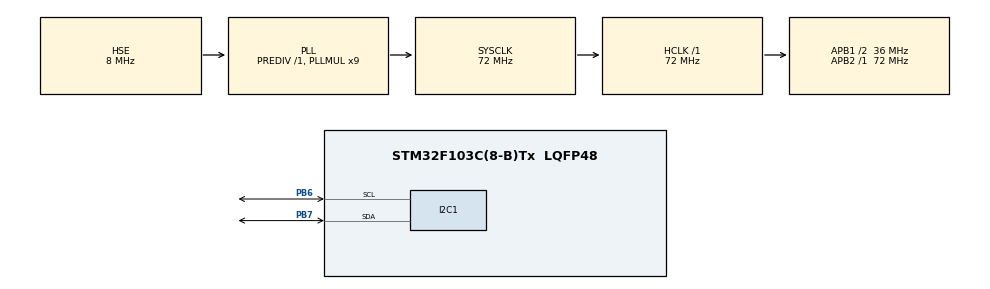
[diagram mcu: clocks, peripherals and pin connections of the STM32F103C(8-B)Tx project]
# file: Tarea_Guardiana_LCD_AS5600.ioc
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Mcu.Family=STM32F1
RCC.PLLSourceVirtual=RCC_PLLSOURCE_HSE
PD1-OSC_OUT.Mode=HSE-External-Oscillator
NVIC.TIM1_UP_IRQn=true\:0\:0\:false\:false\:true\:false\:true
PD0-OSC_IN.Signal=RCC_OSC_IN
RCC.APB1CLKDivider=RCC_HCLK_DIV2
RCC.SYSCLKSource=RCC_SYSCLKSOURCE_PLLCLK
ProjectManager.StackSize=0x400
PD1-OSC_OUT.Signal=RCC_OSC_OUT
PA13.Signal=SYS_JTMS-SWDIO
ProjectManager.TargetToolchain=STM32CubeIDE
RCC.HCLKFreq_Value=72000000
RCC.APB2TimFreq_Value=72000000
PB6.Signal=I2C1_SCL
PB6.Mode=I2C
RCC.USBFreq_Value=72000000
RCC.AHBFreq_Value=72000000
PD0-OSC_IN.Mode=HSE-External-Oscillator
board=custom
RCC.PLLMUL=RCC_PLL_MUL9
RCC.APB2Freq_Value=72000000
PA14.Mode=Serial_Wire
VP_SYS_VS_tim1.Mode=TIM1
PB7.Signal=I2C1_SDA
PA13.Mode=Serial_Wire
Mcu.Name=STM32F103C(8-B)Tx
RCC.SYSCLKFreq_VALUE=72000000
Mcu.Package=LQFP48
NVIC.TimeBase=TIM1_UP_IRQn
PB7.Mode=I2C
NVIC.TimeBaseIP=TIM1
PA14.Signal=SYS_JTCK-SWCLK
ProjectManager.HeapSize=0x200
NVIC.PriorityGroup=NVIC_PRIORITYGROUP_4
RCC.APB1TimFreq_Value=72000000
RCC.APB1Freq_Value=36000000

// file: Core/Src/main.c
/* USER CODE BEGIN Header */
/**
  ******************************************************************************
  * @file           : main.c
  * @brief          : Main program body
  ******************************************************************************
  * @attention
  *
  * <h2><center>&copy; Copyright (c) 2025 STMicroelectronics.
  * All rights reserved.</center></h2>
  *
  * This software component is licensed by ST under BSD 3-Clause license,
  * the "License"; You may not use this file except in compliance with the
  * License. You may obtain a copy of the License at:
  *                        opensource.org/licenses/BSD-3-Clause
  *
  ******************************************************************************
  */
/* USER CODE END Header */
#include "main.h"
#include "FreeRTOS.h"
#include "task.h"
#include "queue.h"
#include "lcd_i2c.h"
#include <stdio.h>
#include "i2c_shared.h"

I2C_HandleTypeDef hi2c1;

/* USER CODE BEGIN PV */

QueueHandle_t I2C_txQueue;
QueueHandle_t I2C_rxQueue;
QueueHandle_t angleQueue;

/* USER CODE END PV */

void SystemClock_Config(void);
static void MX_GPIO_Init(void);
static void MX_I2C1_Init(void);

/* USER CODE BEGIN 0 */

void I2C_controllerTask(void *pvParameters) {
    i2cQueue_t i2cq;
    uint8_t temp[8];

    while (1) {
        xQueueReceive(I2C_txQueue, &i2cq, portMAX_DELAY);

        if (i2cq.type == RECEIVE) {
            HAL_I2C_Master_Transmit(&hi2c1, i2cq.device_id, &i2cq.reg, 1, 10);
            HAL_I2C_Master_Receive(&hi2c1, i2cq.device_id, temp, i2cq.n_bytes, 10);
            xQueueSend(I2C_rxQueue, temp, portMAX_DELAY);
        } else {
            temp[0] = i2cq.reg;
            for (uint8_t i = 0; i < i2cq.n_bytes; i++) {
                temp[i + 1] = i2cq.data[i];
            }
            HAL_I2C_Master_Transmit(&hi2c1, i2cq.device_id, temp, i2cq.n_bytes + 1, 10);
        }
    }
}

void as5600_readerTask(void *pvParameters) {
    uint8_t raw_data[2];
    float angle_deg;

    i2cQueue_t i2cq;
    i2cq.device_id = 0x36 << 1;
    i2cq.reg = 0x0E;  // ANGLE register (MSB)
    i2cq.type = RECEIVE;
    i2cq.n_bytes = 2;
    i2cq.data = raw_data;

    while (1) {
        xQueueSend(I2C_txQueue, &i2cq, portMAX_DELAY);
        xQueueReceive(I2C_rxQueue, raw_data, portMAX_DELAY);

        uint16_t raw_angle = ((uint16_t)raw_data[0] << 8) | raw_data[1];
        angle_deg = (float)raw_angle * 360.0f / 4096.0f;

        xQueueSend(angleQueue, &angle_deg, portMAX_DELAY);
        vTaskDelay(pdMS_TO_TICKS(100));
    }
}

void lcd_displayTask(void *pvParameters) {
    float angle;
    char buffer[16];

    lcd_init();
    lcd_clear();

    while (1) {
        xQueueReceive(angleQueue, &angle, portMAX_DELAY);

        snprintf(buffer, sizeof(buffer), "Angulo: %.1f", angle);
        lcd_goto_XY(0, 0);
        lcd_send_string(buffer);
    }
}

/* USER CODE END 0 */

int main(void)
{

  /* MCU Configuration--------------------------------------------------------*/

  /* Reset of all peripherals, Initializes the Flash interface and the Systick. */
  HAL_Init();

  /* Configure the system clock */
  SystemClock_Config();

  /* Initialize all configured peripherals */
  MX_GPIO_Init();
  MX_I2C1_Init();

  /* Infinite loop */
  /* USER CODE BEGIN WHILE */

     I2C_txQueue = xQueueCreate(4, sizeof(i2cQueue_t));
     I2C_rxQueue = xQueueCreate(4, sizeof(uint8_t) * 2);
     angleQueue  = xQueueCreate(2, sizeof(float));

     xTaskCreate(I2C_controllerTask, "I2C_Guardian", 256, NULL, 2, NULL);
     xTaskCreate(as5600_readerTask, "AS5600", 256, NULL, 1, NULL);
     xTaskCreate(lcd_displayTask, "LCD", 256, NULL, 1, NULL);

     vTaskStartScheduler();

  while (1)
  {
    /* USER CODE END WHILE */

  }
}

void SystemClock_Config(void)
{
  RCC_OscInitTypeDef RCC_OscInitStruct = {0};
  RCC_ClkInitTypeDef RCC_ClkInitStruct = {0};

  /** Initializes the RCC Oscillators according to the specified parameters
  * in the RCC_OscInitTypeDef structure.
  */
  RCC_OscInitStruct.OscillatorType = RCC_OSCILLATORTYPE_HSE;
  RCC_OscInitStruct.HSEState = RCC_HSE_ON;
  RCC_OscInitStruct.HSEPredivValue = RCC_HSE_PREDIV_DIV1;
  RCC_OscInitStruct.HSIState = RCC_HSI_ON;
  RCC_OscInitStruct.PLL.PLLState = RCC_PLL_ON;
  RCC_OscInitStruct.PLL.PLLSource = RCC_PLLSOURCE_HSE;
  RCC_OscInitStruct.PLL.PLLMUL = RCC_PLL_MUL9;
  if (HAL_RCC_OscConfig(&RCC_OscInitStruct) != HAL_OK)
  {
    Error_Handler();
  }
  /** Initializes the CPU, AHB and APB buses clocks
  */
  RCC_ClkInitStruct.ClockType = RCC_CLOCKTYPE_HCLK|RCC_CLOCKTYPE_SYSCLK
                              |RCC_CLOCKTYPE_PCLK1|RCC_CLOCKTYPE_PCLK2;
  RCC_ClkInitStruct.SYSCLKSource = RCC_SYSCLKSOURCE_PLLCLK;
  RCC_ClkInitStruct.AHBCLKDivider = RCC_SYSCLK_DIV1;
  RCC_ClkInitStruct.APB1CLKDivider = RCC_HCLK_DIV2;
  RCC_ClkInitStruct.APB2CLKDivider = RCC_HCLK_DIV1;

  if (HAL_RCC_ClockConfig(&RCC_ClkInitStruct, FLASH_LATENCY_2) != HAL_OK)
  {
    Error_Handler();
  }
}

static void MX_I2C1_Init(void)
{

  hi2c1.Instance = I2C1;
  hi2c1.Init.ClockSpeed = 100000;
  hi2c1.Init.DutyCycle = I2C_DUTYCYCLE_2;
  hi2c1.Init.OwnAddress1 = 0;
  hi2c1.Init.AddressingMode = I2C_ADDRESSINGMODE_7BIT;
  hi2c1.Init.DualAddressMode = I2C_DUALADDRESS_DISABLE;
  hi2c1.Init.OwnAddress2 = 0;
  hi2c1.Init.GeneralCallMode = I2C_GENERALCALL_DISABLE;
  hi2c1.Init.NoStretchMode = I2C_NOSTRETCH_DISABLE;
  if (HAL_I2C_Init(&hi2c1) != HAL_OK)
  {
    Error_Handler();
  }

}

static void MX_GPIO_Init(void)
{

  /* GPIO Ports Clock Enable */
  __HAL_RCC_GPIOD_CLK_ENABLE();
  __HAL_RCC_GPIOA_CLK_ENABLE();
  __HAL_RCC_GPIOB_CLK_ENABLE();

}

 /**
  * @brief  Period elapsed callback in non blocking mode
  * @note   This function is called  when TIM1 interrupt took place, inside
  * HAL_TIM_IRQHandler(). It makes a direct call to HAL_IncTick() to increment
  * a global variable "uwTick" used as application time base.
  * @param  htim : TIM handle
  * @retval None
  */
void HAL_TIM_PeriodElapsedCallback(TIM_HandleTypeDef *htim)
{
  if (htim->Instance == TIM1) {
    HAL_IncTick();
  }
}

void Error_Handler(void)
{
  __disable_irq();
  while (1)
  {
  }
}

/************************ (C) COPYRIGHT STMicroelectronics *****END OF FILE****/
